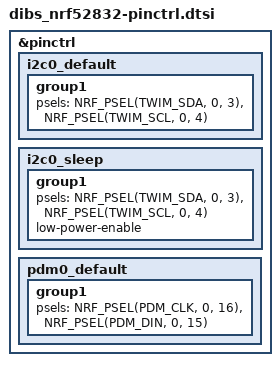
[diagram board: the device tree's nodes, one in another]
&pinctrl {
	i2c0_default: i2c0_default {
		group1 {
			psels = <NRF_PSEL(TWIM_SDA, 0, 3)>,
				<NRF_PSEL(TWIM_SCL, 0, 4)>;
		};
	};

	i2c0_sleep: i2c0_sleep {
		group1 {
			psels = <NRF_PSEL(TWIM_SDA, 0, 3)>,
				<NRF_PSEL(TWIM_SCL, 0, 4)>;
			low-power-enable;
		};
	};

	pdm0_default: pdm0_default {
		group1 {
			psels = <NRF_PSEL(PDM_CLK, 0, 16)>,
				<NRF_PSEL(PDM_DIN, 0, 15)>;
		};
	};
};
